# A31T41x register map
Vendor: ABOV Semiconductor Co., Ltd.; File version: 1.0
CPU: CM0PLUS r0p1, little endian, no MPU, no FPU, VTOR, vendor SysTick, 2 interrupt priority bits
Registers are 32-bit, read-write, reset 0x0 unless marked. A register's access mark holds for its fields unless they carry their own. Offsets are from the block's base; [hi:lo] are bit positions; {n}, {i} and the like mark numbered series.

## PORTRSTDBCR — General Port Reset Debounce Enable
Base 0x40090F0C
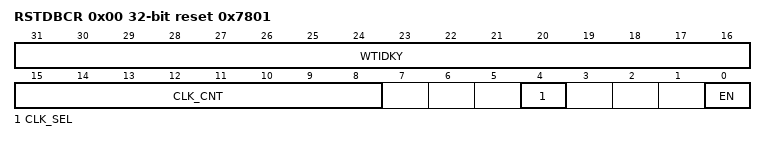
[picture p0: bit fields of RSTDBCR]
0x00 RSTDBCR reset 0x7801 — Port Reset Debounce Control Register
  [31:16] WTIDKY — Write Identification Key
  [15:8] CLK_CNT — Noise cancelling delay option for selected debounce clock
  [4] CLK_SEL — Debounce clock selection
  [0] EN — Pin reset debounce enable
    0=Disable (Pin reset debounce diable); 1=Enable (Pin reset debounce enable)

## PORTEN — General Port Access Enable
Base 0x40090FF0
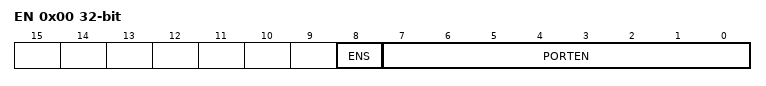
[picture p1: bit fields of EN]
0x00 EN wo — Port Access Enable Register
  [8] ENS ro — Pin Clear bit, x = 0 to 15
  [7:0] PORTEN — PCU and GPIO register access enable (0x15, 0x51)

## DMA — Direct Memory Access Control 0
Base 0x50000400
Same registers: DMA0 0x40000400, DMA1 0x40000410, DMA2 0x40000420, DMA3 0x40000430
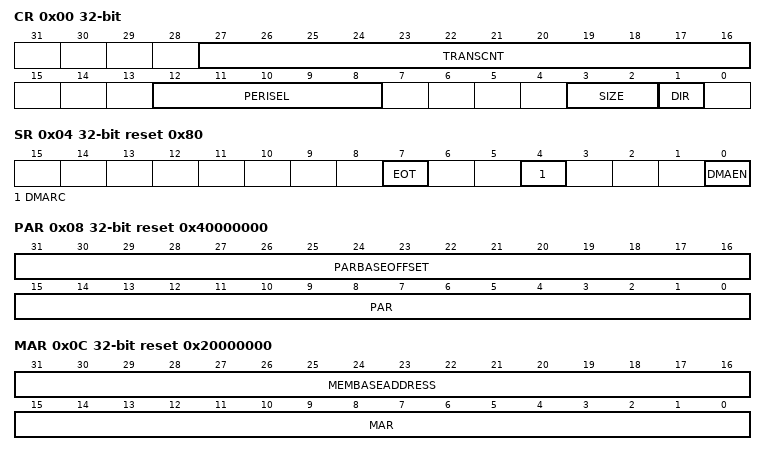
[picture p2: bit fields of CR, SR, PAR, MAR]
0x00 CR — DMA channel n control register
  [27:16] TRANSCNT — Number of DMA transfers Before enabling
  [12:8] PERISEL — Peripheral selection
  [3:2] SIZE — Bus transfer size
    0=Byte (transmit byte size); 1=half_word (transmit half word size); 2=word (transmit word size)
  [1] DIR — Transfer direction selection
    0=MEM-PERI (Memory->Peripheral); 1=PERI-MEM (Peripheral->Memory)
0x04 SR reset 0x80 — DMA channel n status register
  [7] EOT ro — Transfer ends
    0=BUSY (There are remaining transfers. TRANSCNT[11:0] has a value other than zero.); 1=EMPTY (All data has been transferred. The TRANSCNT[11:0] value is zero.)
  [4] DMARC — DMA request clear (Auto clear)
    1=Clear (DMA Clear)
  [0] DMAEN — Enables DMA use
0x08 PAR reset 0x40000000 — DMA channel n peripheral address register
  [31:16] PARBASEOFFSET ro — Peripheral base address offset
  [15:0] PAR — Address of the transfer / receive buffers target peripheral
0x0C MAR reset 0x20000000 — DMA channel n memory address register
  [31:16] MEMBASEADDRESS ro — Memory base address offset
  [15:0] MAR — Target memory address of the data transfer

## WDT — WATCH-DOG TIMER
Base 0x40000200
0x00 LR — WDT load register
  [31:0] LR — WDT load value register
0x04 CNT reset 0x7D0 — WDT current count register
  [31:0] CNT ro — WDT current counter register
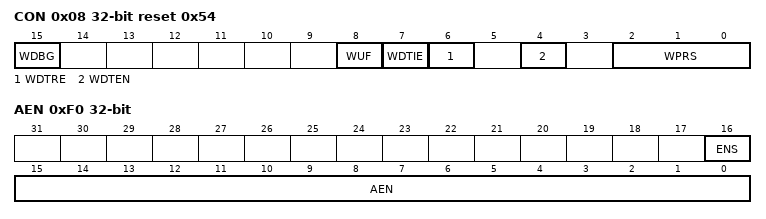
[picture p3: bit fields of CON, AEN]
0x08 CON reset 0x54 — WDT control register
  [15] WDBG — Whether to enable or disable the WDT in debug mode
  [8] WUF — WDT underflow flag (The bit is cleared when WDT_LR is written.)
  [7] WDTIE — Whether to enable or disable the WDT counter underflow interrupt
  [6] WDTRE — Whether to enable or disable the WDT counter underflow reset
  [4] WDTEN — Whether to enable or disable the WDT counter
  [2:0] WPRS — Counter clock prescaler
    0=WDTCLKIN_DIV_BY_1 (WDT Input Clock divide by 1); 1=WDTCLKIN_DIV_BY_4 (WDT Input Clock divide by 4); 2=WDTCLKIN_DIV_BY_8 (WDT Input Clock divide by 8); 3=WDTCLKIN_DIV_BY_16 (WDT Input Clock divide by 16); 4=WDTCLKIN_DIV_BY_32 (WDT Input Clock divide by 32); 5=WDTCLKIN_DIV_BY_64 (WDT Input Clock divide by 64); 6=WDTCLKIN_DIV_BY_128 (WDT Input Clock divide by 128); 7=WDTCLKIN_DIV_BY_256 (WDT Input Clock divide by 256)
0xF0 AEN — WDT access enable register
  [16] ENS ro — Enable status bit
  [15:0] AEN wo — Enable the write access of WDT registers (0xA55A)

## TIMER — TIMER COUNTER 0
Base 0x50003000
Same registers: TIMER0 0x40003000, TIMER1 0x40003040, TIMER2 0x40003080, TIMER3 0x400030C0, TIMER4 0x40003100
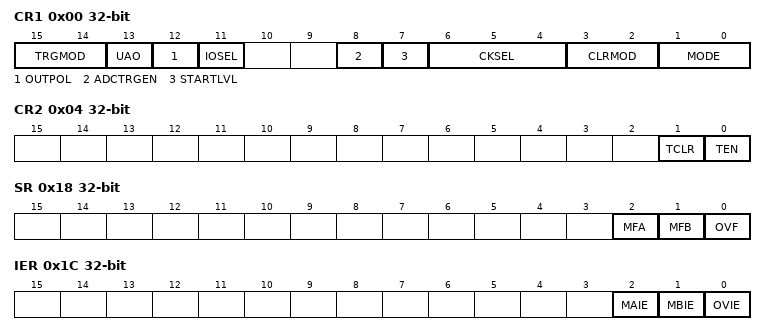
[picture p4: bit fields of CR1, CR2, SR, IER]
0x00 CR1 — Timer / counter n control register 1
  [15:14] TRGMOD — ADC trigger mode selection
    0=GRA (GRA Value Trigger Mode (Normal Mode)); 2=TRGPNT (TRGPNT Value Trigger Mode); 3=GRA_TRGPNT (GRA, TRGPNT Value Both Trigger Mode)
  [13] UAO — GRA / GRB update mode selection
    0=Next_Period (Write Value Apply to next period); 1=Current_Period (Write value apply to current period)
  [12] OUTPOL — Timer output polarity
    0=Normal Output; 1=Polarity (Polairty Output)
  [11] IOSEL — Timer output polarity
    0=Input (Timer Input Port Setting); 1=Output (Timer Output Port Setting)
  [8] ADCTRGEN — Whether or not to use the timer as an ADC trigger source
    0=No_Used; 1=Used
  [7] STARTLVL — Starting output value in periodic / PWM / one-shot modes
    0=Low (Output Start Low); 1=High (Output Start High)
  [6:4] CKSEL — Counter clock source selection
    0=PCLK/2 (Counter Clock is PCLK/2); 1=PCLK/4 (Counter Clock is PCLK/4); 2=PCLK/16 (Counter Clock is PCLK/16); 3=PCLK/64 (Counter Clock is PCLK/64); 4=EXT0(MCCR3) (Counter Clock is EXT0(MCCR3)); 6=TnIO (Counter Clock is TnIO (input pin))
  [3:2] CLRMOD — Clear mode selection in capture mode
    0=Rising Edge Clear Mode; 1=Falling Edge Clear Mode; 2=Both (Rising/Falling Edge Clear Mode); 3=Not Clear Mode
  [1:0] MODE — Timer operation mode control
    0=Interval (Timer is Interval Mode); 1=PWM (Timer is PWM Mode); 2=One-shot (Timer is One-Shot Mode); 3=Capture (Timer is Capture Mode)
0x04 CR2 — Timer / counter n control register 2
  [1] TCLR wo — Clearing of the timer count register
  [0] TEN — Whether to enable or disable the timer
    0=Disable (Timer Disable); 1=Enable (Timer Enable)
0x08 PRS — Timer / counter n prescaler register
  [9:0] PRS — Counter Clock Prescaler Value, TCLK=CLOCK_IN/(PRS+1)
0x0C GRA — Timer / counter n general data register A
  [15:0] GRA — Timer general register A
0x10 GRB — Timer / counter n general data register B
  [15:0] GRB — Timer general register B
0x14 CNT — Timer / counter n count register
  [15:0] CNT — Timer count value
0x18 SR — Timer / counter n status register
  [2] MFA — TIMERn_GRA match flag
  [1] MFB — TIMERn_GRB match flag
  [0] OVF — Counter overflow flag
0x1C IER — Timer / counter n interrupt enable register
  [2] MAIE — Whether to enable or disable the TIMERn_GRA match interrupt
  [1] MBIE — Whether to enable or disable the TIMERn_GRB match interrupt
  [0] OVIE — Whether to enable or disable the counter overflow interrupt
0x20 TRGPNT — Timer / counter n trigger point register
  [15:0] TRGPNT — Timer trigger point value
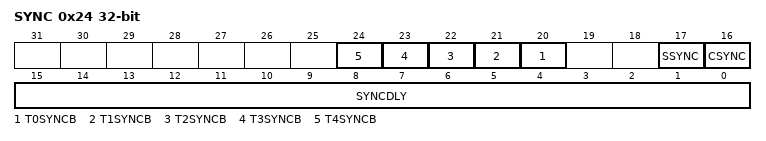
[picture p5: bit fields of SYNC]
0x24 SYNC — Timer / counter n sync configuration register
  [n+20] T{n}SYNCB (n=0..4) — Synchronization settings to Timer {n}
    0=Disable (SYNC Disable); 1=Enable (SYNC Enable)
  [17] SSYNC — Synchronizes other synchronization timer to start counter
    0=Disable (SYNC Disable); 1=Enable (SYNC Enable)
  [16] CSYNC — Synchronizes other synchronization timer to clear counter
    0=Disable (SYNC Disable); 1=Enable (SYNC Enable)
  [15:0] SYNCDLY — SYNC delay start count value setting bit(based on the master counter)
